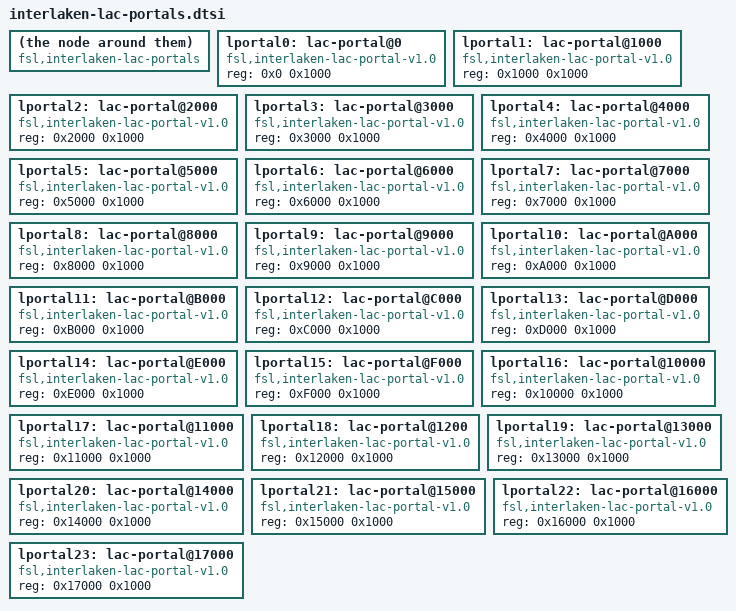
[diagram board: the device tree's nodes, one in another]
/* T4240 Interlaken LAC Portal device tree stub with 24 portals.
 *
 * Copyright 2012 Freescale Semiconductor Inc.
 *
 * Redistribution and use in source and binary forms, with or without
 * modification, are permitted provided that the following conditions are met:
 *     * Redistributions of source code must retain the above copyright
 *       notice, this list of conditions and the following disclaimer.
 *     * Redistributions in binary form must reproduce the above copyright
 *       notice, this list of conditions and the following disclaimer in the
 *       documentation and/or other materials provided with the distribution.
 *     * Neither the name of Freescale Semiconductor nor the
 *       names of its contributors may be used to endorse or promote products
 *       derived from this software without specific prior written permission.
 *
 *
 * ALTERNATIVELY, this software may be distributed under the terms of the
 * GNU General Public License ("GPL") as published by the Free Software
 * Foundation, either version 2 of that License or (at your option) any
 * later version.
 *
 * THIS SOFTWARE IS PROVIDED BY Freescale Semiconductor "AS IS" AND ANY
 * EXPRESS OR IMPLIED WARRANTIES, INCLUDING, BUT NOT LIMITED TO, THE IMPLIED
 * WARRANTIES OF MERCHANTABILITY AND FITNESS FOR A PARTICULAR PURPOSE ARE
 * DISCLAIMED. IN NO EVENT SHALL Freescale Semiconductor BE LIABLE FOR ANY
 * DIRECT, INDIRECT, INCIDENTAL, SPECIAL, EXEMPLARY, OR CONSEQUENTIAL DAMAGES
 * (INCLUDING, BUT NOT LIMITED TO, PROCUREMENT OF SUBSTITUTE GOODS OR SERVICES;
 * LOSS OF USE, DATA, OR PROFITS; OR BUSINESS INTERRUPTION) HOWEVER CAUSED AND
 * ON ANY THEORY OF LIABILITY, WHETHER IN CONTRACT, STRICT LIABILITY, OR TORT
 * (INCLUDING NEGLIGENCE OR OTHERWISE) ARISING IN ANY WAY OUT OF THE USE OF THIS
 * SOFTWARE, EVEN IF ADVISED OF THE POSSIBILITY OF SUCH DAMAGE.
 */

#address-cells = <0x1>;
#size-cells = <0x1>;
compatible = "fsl,interlaken-lac-portals";

lportal0: lac-portal@0 {
	compatible = "fsl,interlaken-lac-portal-v1.0";
	reg = <0x0 0x1000>;
};

lportal1: lac-portal@1000 {
	compatible = "fsl,interlaken-lac-portal-v1.0";
	reg = <0x1000 0x1000>;
};

lportal2: lac-portal@2000 {
	compatible = "fsl,interlaken-lac-portal-v1.0";
	reg = <0x2000 0x1000>;
};

lportal3: lac-portal@3000 {
	compatible = "fsl,interlaken-lac-portal-v1.0";
	reg = <0x3000 0x1000>;
};

lportal4: lac-portal@4000 {
	compatible = "fsl,interlaken-lac-portal-v1.0";
	reg = <0x4000 0x1000>;
};

lportal5: lac-portal@5000 {
	compatible = "fsl,interlaken-lac-portal-v1.0";
	reg = <0x5000 0x1000>;
};

lportal6: lac-portal@6000 {
	compatible = "fsl,interlaken-lac-portal-v1.0";
	reg = <0x6000 0x1000>;
};

lportal7: lac-portal@7000 {
	compatible = "fsl,interlaken-lac-portal-v1.0";
	reg = <0x7000 0x1000>;
};

lportal8: lac-portal@8000 {
	compatible = "fsl,interlaken-lac-portal-v1.0";
	reg = <0x8000 0x1000>;
};

lportal9: lac-portal@9000 {
	compatible = "fsl,interlaken-lac-portal-v1.0";
	reg = <0x9000 0x1000>;
};

lportal10: lac-portal@A000 {
	compatible = "fsl,interlaken-lac-portal-v1.0";
	reg = <0xA000 0x1000>;
};

lportal11: lac-portal@B000 {
	compatible = "fsl,interlaken-lac-portal-v1.0";
	reg = <0xB000 0x1000>;
};

lportal12: lac-portal@C000 {
	compatible = "fsl,interlaken-lac-portal-v1.0";
	reg = <0xC000 0x1000>;
};

lportal13: lac-portal@D000 {
	compatible = "fsl,interlaken-lac-portal-v1.0";
	reg = <0xD000 0x1000>;
};

lportal14: lac-portal@E000 {
	compatible = "fsl,interlaken-lac-portal-v1.0";
	reg = <0xE000 0x1000>;
};

lportal15: lac-portal@F000 {
	compatible = "fsl,interlaken-lac-portal-v1.0";
	reg = <0xF000 0x1000>;
};

lportal16: lac-portal@10000 {
	compatible = "fsl,interlaken-lac-portal-v1.0";
	reg = <0x10000 0x1000>;
};

lportal17: lac-portal@11000 {
	compatible = "fsl,interlaken-lac-portal-v1.0";
	reg = <0x11000 0x1000>;
};

lportal18: lac-portal@1200 {
	compatible = "fsl,interlaken-lac-portal-v1.0";
	reg = <0x12000 0x1000>;
};

lportal19: lac-portal@13000 {
	compatible = "fsl,interlaken-lac-portal-v1.0";
	reg = <0x13000 0x1000>;
};

lportal20: lac-portal@14000 {
	compatible = "fsl,interlaken-lac-portal-v1.0";
	reg = <0x14000 0x1000>;
};

lportal21: lac-portal@15000 {
	compatible = "fsl,interlaken-lac-portal-v1.0";
	reg = <0x15000 0x1000>;
};

lportal22: lac-portal@16000 {
	compatible = "fsl,interlaken-lac-portal-v1.0";
	reg = <0x16000 0x1000>;
};

lportal23: lac-portal@17000 {
	compatible = "fsl,interlaken-lac-portal-v1.0";
	reg = <0x17000 0x1000>;
};
